# AT90PWM81 register map
Vendor: Atmel; File version: 1.0
CPU: other r0p0, little endian, no MPU, no FPU, 4 interrupt priority bits
Registers are 8-bit, read-write, reset 0x0 unless marked. A register's access mark holds for its fields unless they carry their own. Offsets are from the block's base; [hi:lo] are bit positions.

## DAC — Digital-to-Analog Converter
Base 0x00800058
0x00 DAC 16-bit (reset mask 0xFF) — DAC Data Register (write-only for debugger)
  [9:0] DACH — DAC Data Register Bits
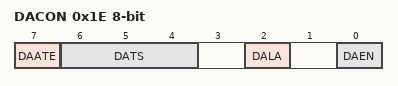
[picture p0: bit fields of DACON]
0x1E DACON — DAC Control Register
  [7] DAATE — DAC Auto Trigger Enable Bit
  [6:4] DATS — DAC Trigger Selection Bits
    0=ANALOG_COMPARATOR_0; 1=ANALOG_COMPARATOR_1; 2=EXTERNAL_INTERRUPT_REQUEST_0; 3=TIMER_COUNTER0_COMPARE_MATCH_A; 4=TIMER_COUNTER0_OVERFLOW; 5=TIMER_COUNTER1_COMPARE_MATCH_B; 6=TIMER_COUNTER1_OVERFLOW; 7=TIMER_COUNTER1_CAPTURE_EVENT
  [2] DALA — DAC Left Adjust
  [0] DAEN — DAC Enable Bit

## EEPROM
Base 0x0080003C
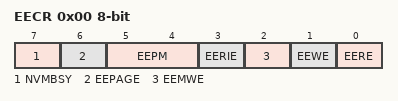
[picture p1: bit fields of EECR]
0x00 EECR — EEPROM Control Register
  [7] NVMBSY — None Volatile Busy Memory Busy
  [6] EEPAGE — EEPROM Page Access
  [5:4] EEPM — EEPROM Programming Mode
  [3] EERIE — EEPROM Ready Interrupt Enable
  [2] EEMWE — EEPROM Master Write Enable
  [1] EEWE — EEPROM Write Enable
  [0] EERE — EEPROM Read Enable
0x01 EEDR — EEPROM Data Register
  [7:0] EEDR — EEPROM Data bits
0x02 EEAR 16-bit (reset mask 0xFF) — EEPROM Read/Write Access Bytes
  [8:0] EEAR — EEPROM Address bytes

## EXINT — External Interrupts
Base 0x00800040
0x00 EIFR — External Interrupt Flag Register (read-only for debugger)
  [2:0] INTF — External Interrupt Flags
0x01 EIMSK — External Interrupt Mask Register
  [2:0] INT — External Interrupt Request 2 Enable
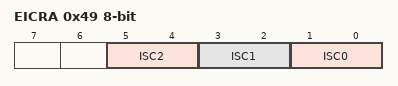
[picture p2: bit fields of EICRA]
0x49 EICRA — External Interrupt Control Register A
  [all] fields
    0=LOW_LEVEL_OF_INTX; 1=ANY_LOGICAL_CHANGE_OF_INTX; 2=FALLING_EDGE_OF_INTX; 3=RISING_EDGE_OF_INTX
  [5:4] ISC2 — External Interrupt Sense Control Bit
  [3:2] ISC1 — External Interrupt Sense Control Bit
  [1:0] ISC0 — External Interrupt Sense Control Bit

## LOCKBIT — Lockbits
Base 0x00800000
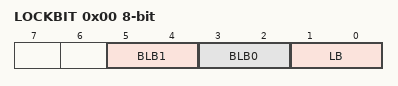
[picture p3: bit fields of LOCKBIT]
0x00 LOCKBIT
  [5:4] BLB1 — Boot Loader Protection Mode
    0=LPM_SPM_DISABLE (LPM and SPM prohibited in Boot Section); 1=LPM_DISABLE (LPM prohibited in Boot Section); 2=SPM_DISABLE (SPM prohibited in Boot Section); 3=NO_LOCK (No lock on SPM and LPM in Boot Section)
  [3:2] BLB0 — Boot Loader Protection Mode
    0=LPM_SPM_DISABLE (LPM and SPM prohibited in Application Section); 1=LPM_DISABLE (LPM prohibited in Application Section); 2=SPM_DISABLE (SPM prohibited in Application Section); 3=NO_LOCK (No lock on SPM and LPM in Application Section)
  [1:0] LB — Memory Lock
    0=PROG_VER_DISABLED (Further programming and verification disabled); 2=PROG_DISABLED (Further programming disabled); 3=NO_LOCK (No memory lock features enabled)

## PORTB — I/O Port
Base 0x00800023
0x00 PINB — Port B Input Pins (read-only for debugger)
0x01 DDRB — Port B Data Direction Register
0x02 PORTB — Port B Data Register

## PORTD — I/O Port
Base 0x00800029
0x00 PIND — Port D Input Pins (read-only for debugger)
0x01 DDRD — Port D Data Direction Register
0x02 PORTD — Port D Data Register

## PORTE — I/O Port
Base 0x0080002C
0x00 PINE — Port E Input Pins (read-only for debugger)
0x01 DDRE — Port E Data Direction Register
0x02 PORTE — Port E Data Register

## PSC0 — Power Stage Controller
Base 0x0080002F
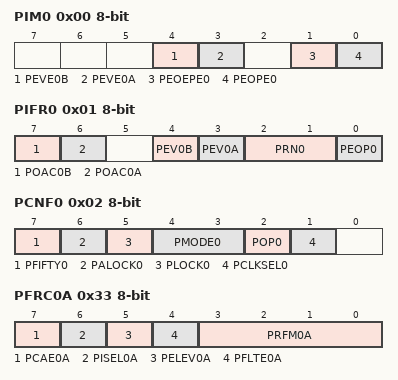
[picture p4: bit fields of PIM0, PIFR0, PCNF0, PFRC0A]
0x00 PIM0 — PSC0 Interrupt Mask Register
  [4] PEVE0B — External Event B Interrupt Enable
  [3] PEVE0A — External Event A Interrupt Enable
  [1] PEOEPE0 — End of Enhanced Cycle Enable
  [0] PEOPE0 — End of Cycle Interrupt Enable
0x01 PIFR0 — PSC0 Interrupt Flag Register
  [7] POAC0B — PSC 0 Output A Activity
  [6] POAC0A — PSC 0 Output A Activity
  [4] PEV0B — External Event B Interrupt
  [3] PEV0A — External Event A Interrupt
  [2:1] PRN0 — Ramp Number
  [0] PEOP0 — End of PSC0 Interrupt
0x02 PCNF0 — PSC 0 Configuration Register
  [7] PFIFTY0 — PSC 0 Fifty
  [6] PALOCK0 — PSC 0 Autolock
  [5] PLOCK0 — PSC 0 Lock
  [4:3] PMODE0 — PSC 0 Mode
  [2] POP0 — PSC 0 Output Polarity
  [1] PCLKSEL0 — PSC 0 Input Clock Select
0x03 PCTL0 — PSC 0 Control Register
  [7:6] PPRE0 — PSC 0 Prescaler Selects
  [4] PAOC0B — PSC 0 Asynchronous Output Control B
  [3] PAOC0A — PSC 0 Asynchronous Output Control A
  [5:2] PBFM0 — PSC 0 Balance Flank Width Modulation
  [1] PCCYC0 — PSC0 Complete Cycle
  [0] PRUN0 — PSC 0 Run
0x13 OCR0SB 16-bit (reset mask 0xFF) — Output Compare SB Register
  [11:0] OCR0SB — Output Compare 0 SB
0x15 OCR0RB 16-bit (reset mask 0xFF) — Output Compare RB Register
  [15:0] OCR0RB — Output Compare 0 RB
0x1B OCR0RA 16-bit (reset mask 0xFF) — Output Compare RA Register
  [11:0] OCR0RA — Output Compare 0 RA
0x31 OCR0SA 16-bit (reset mask 0xFF) — Output Compare SA Register
  [11:0] OCR0SA — Output Compare 0 SA
0x33 PFRC0A — PSC 0 Input A Control
  [7] PCAE0A — PSC 0 Capture Enable Input Part A
  [6] PISEL0A — PSC 0 Input Select for Part A
  [5] PELEV0A — PSC 0 Edge Level Selector on Input Part A
  [4] PFLTE0A — PSC 0 Filter Enable on Input Part A
  [3:0] PRFM0A — PSC 0 Retrigger and Fault Mode for Part A
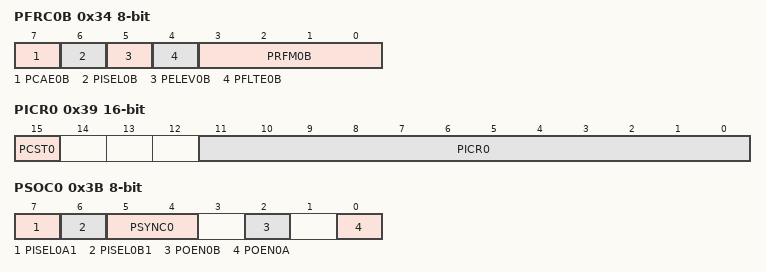
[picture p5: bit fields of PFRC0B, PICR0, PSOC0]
0x34 PFRC0B — PSC 0 Input B Control
  [7] PCAE0B — PSC 0 Capture Enable Input Part B
  [6] PISEL0B — PSC 0 Input Select for Part B
  [5] PELEV0B — PSC 0 Edge Level Selector on Input Part B
  [4] PFLTE0B — PSC 0 Filter Enable on Input Part B
  [3:0] PRFM0B — PSC 0 Retrigger and Fault Mode for Part B
0x39 PICR0 16-bit (reset mask 0xFF) — PSC 0 Input Capture Register
  [15] PCST0 — PSC 0 Capture Software Trigger Bit
  [11:0] PICR0 — PSC 0 Input Capture Bytes
0x3B PSOC0 — PSC0 Synchro and Output Configuration
  [7] PISEL0A1 — PSC Input Select
  [6] PISEL0B1 — PSC Input Select
  [5:4] PSYNC0 — Synchronisation out for ADC selection
  [2] POEN0B — PSCOUT01 Output Enable
  [0] POEN0A — PSCOUT00 Output Enable
